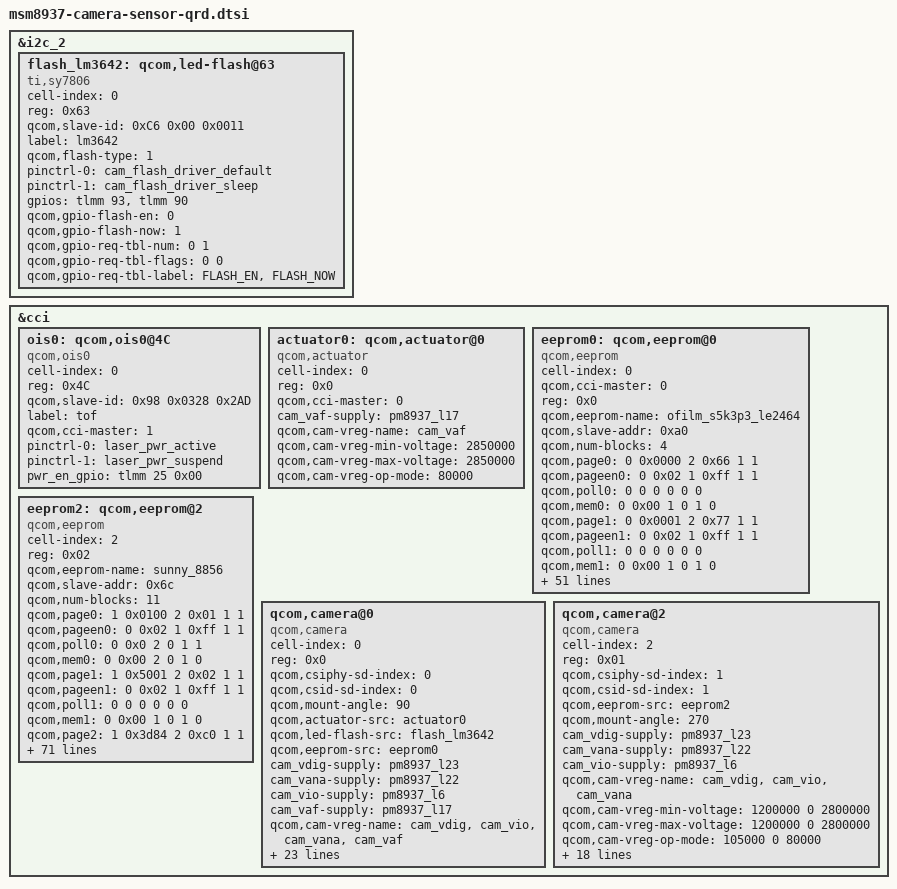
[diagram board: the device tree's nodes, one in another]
/*
 * Copyright (c) 2015-2016, The Linux Foundation. All rights reserved.
 *
 * This program is free software; you can redistribute it and/or modify
 * it under the terms of the GNU General Public License version 2 and
 * only version 2 as published by the Free Software Foundation.
 *
 * This program is distributed in the hope that it will be useful,
 * but WITHOUT ANY WARRANTY; without even the implied warranty of
 * MERCHANTABILITY or FITNESS FOR A PARTICULAR PURPOSE.  See the
 * GNU General Public License for more details.
 */

 //add by allen yao for flash driver ic
&i2c_2 {
	flash_lm3642:qcom,led-flash@63 {
		cell-index = <0>;
		reg = <0x63>;
		qcom,slave-id = <0xC6 0x00 0x0011>;
		compatible = "ti,sy7806";
		label = "lm3642";
		qcom,flash-type = <1>;
		pinctrl-names = "cam_flash_driver_default","cam_flash_driver_sleep";
		pinctrl-0 = <&cam_flash_driver_default>;
		pinctrl-1 = <&cam_flash_driver_sleep>;
		gpios = <&tlmm 93 0>,
			<&tlmm 90 0>;
		qcom,gpio-flash-en = <0>;
		qcom,gpio-flash-now = <1>;
		qcom,gpio-req-tbl-num = <0 1>;
		qcom,gpio-req-tbl-flags = <0 0>;
		qcom,gpio-req-tbl-label = "FLASH_EN",
			"FLASH_NOW";
	};

};

 
&cci {

	ois0: qcom,ois0@4C {
		cell-index = <0>;
		reg = <0x4C>;
		qcom,slave-id = <0x98 0x0328 0x2AD>;
		compatible = "qcom,ois0";
		label = "tof";
		qcom,cci-master = <1>;
		pinctrl-names = "laser_active","laser_suspend";
		pinctrl-0 = <&laser_pwr_active>;
		pinctrl-1 = <&laser_pwr_suspend>;
		pwr_en_gpio = <&tlmm 25 0x00>;
		/*
		laser_power-supply = <&pm8937_l10>;
		cam_cci-supply = <&pm8937_l6>;
		qcom,cam-vreg-name = "laser_power","cam_cci";
		qcom,cam-vreg-min-voltage = <2850000 1800000>;
		qcom,cam-vreg-max-voltage = <2900000 1800000>;
		qcom,cam-vreg-op-mode = <80000 100000>;
		*/
	};

	actuator0: qcom,actuator@0 {
		cell-index = <0>;
		reg = <0x0>;
		compatible = "qcom,actuator";
		qcom,cci-master = <0>;
		cam_vaf-supply = <&pm8937_l17>;
		qcom,cam-vreg-name = "cam_vaf";
		qcom,cam-vreg-min-voltage = <2850000>;
		qcom,cam-vreg-max-voltage = <2850000>;
		qcom,cam-vreg-op-mode = <80000>;
	};

	eeprom0: qcom,eeprom@0 {
		cell-index = <0>;
		compatible = "qcom,eeprom";
		qcom,cci-master = <0>;
		reg = <0x0>;

		//add by allenyao
		qcom,eeprom-name = "ofilm_s5k3p3_le2464";
		//compatible = "qcom,eeprom";
		qcom,slave-addr = <0xa0>;
		//qcom,cci-master = <0>;
		qcom,num-blocks = <4>;
		
		qcom,page0 = <0 0x0000 2 0x66 1 1>;
		qcom,pageen0 = <0 0x02 1 0xff 1 1>;
		qcom,poll0 = <0 0 0 0 0 0>;
		qcom,mem0 = <0 0x00 1 0 1 0>;
		
		qcom,page1 = < 0 0x0001 2 0x77 1 1>;
		qcom,pageen1 = <0 0x02 1 0xff 1 1>;
		qcom,poll1 = <0 0 0 0 0 0>;
		qcom,mem1 = <0 0x00 1 0 1 0>;

		qcom,page2 = <0 0x0002 2 0x88 1 1>;
		qcom,pageen2 = <0 0x02 1 0xff 1 1>;
		qcom,poll2 = <0 0 0 0 0 0>;
		qcom,mem2 = <0 0x00 1 0 1 0>;

		qcom,page3 = <0 0x00 1 0x55 1 1>;
		qcom,pageen3 = <0 0x02 1 0xff 1 1>;
		qcom,poll3 = <0 0x0 2 0 1 1>;
		qcom,mem3 = <2205 0x00 2 0 1 0>;
		
		qcom,saddr4 = <0xaa>;
		qcom,page4 = <0 0x00 1 0x99 1 1>;
		qcom,pageen4 = <0 0x02 1 0xff 1 1>;
		qcom,poll4 = <0 0 0 0 0 0>;
		qcom,mem4 = <255 0x00 1 0 1 0>;
		
		qcom,saddr5 = <0xac>;
		qcom,page5 = <0 0x00 1 0x11 1 1>;
		qcom,pageen5 = <0 0x02 1 0xff 1 1>;
		qcom,poll5 = <0 0 0 0 0 0>;
		qcom,mem5 = <85 0x00 1 0 1 0>;
		//end 

		
		cam_vdig-supply = <&pm8937_l23>;
		cam_vana-supply = <&pm8937_l22>;
		cam_vio-supply = <&pm8937_l6>;
		cam_vaf-supply = <&pm8937_l17>;
		qcom,cam-vreg-name = "cam_vdig", "cam_vio", "cam_vana",
							"cam_vaf";
		qcom,cam-vreg-min-voltage = <1200000 0 2800000 2850000>;
		qcom,cam-vreg-max-voltage = <1200000 0 2800000 2850000>;
		qcom,cam-vreg-op-mode = <200000 0 80000 100000>;
		pinctrl-names = "cam_default", "cam_suspend";
		pinctrl-0 = <&cam_sensor_mclk0_default
				&cam_sensor_rear_default>;
		pinctrl-1 = <&cam_sensor_mclk0_sleep &cam_sensor_rear_sleep>;
		gpios = <&tlmm 26 0>,
			<&tlmm 36 0>,
			<&tlmm 42 0>;
		qcom,gpio-reset = <1>;
		qcom,gpio-standby = <2>;
		qcom,gpio-req-tbl-num = <0 1 2>;
		qcom,gpio-req-tbl-flags = <1 0 0>;
		qcom,gpio-req-tbl-label = "CAMIF_MCLK0",
			"CAM_RESET0",
			"CAM_STANDBY0";
		status = "ok";

		//add by allenyao
		qcom,cam-power-seq-type = "sensor_vreg",
			"sensor_vreg", "sensor_vreg",
			"sensor_gpio", "sensor_gpio",
			"sensor_clk";
		qcom,cam-power-seq-val = "cam_vio",
			"cam_vana", "cam_vdig",
			"sensor_gpio_reset",
			"sensor_gpio_standby",
			"sensor_cam_mclk" ;
		qcom,cam-power-seq-cfg-val = <1 1 1 1 1 24000000>;
		qcom,cam-power-seq-delay = <10 10 10 10 10 5>;
		//end
		
		clocks = <&clock_gcc clk_mclk0_clk_src>,
				<&clock_gcc clk_gcc_camss_mclk0_clk>;
		clock-names = "cam_src_clk", "cam_clk";
		qcom,clock-rates = <19200000 0>;
	};

	eeprom2: qcom,eeprom@2 {
		cell-index = <2>;
		compatible = "qcom,eeprom";
		reg = <0x02>;
		
		//add by allenyao
		qcom,eeprom-name = "sunny_8856";
		//compatible = "qcom,eeprom";
		qcom,slave-addr = <0x6c>;
		//qcom,cci-master = <0>;
		qcom,num-blocks = <11>;
		
		qcom,page0 = <1 0x0100 2 0x01 1 1>;
		qcom,pageen0 = <0 0x02 1 0xff 1 1>;
		qcom,poll0 = <0 0x0 2 0 1 1>;
		qcom,mem0 = <0 0x00 2 0 1 0>;

		qcom,page1 = <1 0x5001 2 0x02 1 1>;
		qcom,pageen1 = <0 0x02 1 0xff 1 1>;
		qcom,poll1 = <0 0 0 0 0 0>;
		qcom,mem1 = <0 0x00 1 0 1 0>;
		
		qcom,page2 = <1 0x3d84 2 0xc0 1 1>;
		qcom,pageen2 = <0 0x02 1 0xff 1 1>;
		qcom,poll2 = <0 0 0 0 0 0>;
		qcom,mem2 = <0 0x00 1 0 1 0>;

		qcom,page3 = <1 0x3d88 2 0x70 1 1>;//start high add
		qcom,pageen3 = <0 0x02 1 0xff 1 1>;
		qcom,poll3 = <0 0 0 0 0 0>;
		qcom,mem3 = <0 0x00 1 0 1 0>;
		
		qcom,page4 = <1 0x3d89 2 0x10 1 1>;//start low add
		qcom,pageen4 = <0 0x02 1 0xff 1 1>;
		qcom,poll4 = <0 0 0 0 0 0>;
		qcom,mem4 = <0 0x00 1 0 1 0>;
		
		qcom,page5 = <1 0x3d8a 2 0x72 1 1>;//end high add
		qcom,pageen5 = <0 0x02 1 0xff 1 1>;
		qcom,poll5 = <0 0 0 0 0 0>;
		qcom,mem5 = <0 0x00 1 0 1 0>;

		qcom,page6 = <1 0x3d8b 2 0x03 1 1>;//end low add
		qcom,pageen6 = <0 0x02 1 0xff 1 1>;
		qcom,poll6 = <0 0 0 0 0 0>;
		qcom,mem6 = <0 0x00 1 0 1 0>;

		qcom,page7 = <1 0x3d81 2 0x01 1 10>;//load otp data into buffer
		qcom,pageen7 = <0 0x02 1 0xff 1 1>;
		qcom,poll7 = <0 0 0 0 0 0>;
		qcom,mem7 = <0 0x7203 2 0 1 0>;

		qcom,page8 = <0 0x00 1 0x11 1 1>;
		qcom,pageen8 = <0 0x02 1 0xff 1 1>;
		qcom,poll8 = <0 0 0 0 0 0>;
		qcom,mem8 = <500 0x7010 2 0 1 0>; //read data
		
		qcom,page9 = <0 0x00 1 0x11 1 1>;
		qcom,pageen9 = <0 0x02 1 0xff 1 1>;
		qcom,poll9 = <0 0 0 0 0 0>;
		qcom,mem9 = <0 0x00 1 0 1 0>;
		qcom,clear9 = <500 0x7010 2 0 1 0>; //clear buff

		qcom,page10 = <1 0x5001 2 0x0a 1 1>;
		qcom,pageen10 = <0 0x02 1 0xff 1 1>;
		qcom,poll10 = <0 0 0 0 0 0>;
		qcom,mem10 = <0 0x7203 2 0 1 0>;
		//end 
		
		cam_vdig-supply = <&pm8937_l23>;
		cam_vana-supply = <&pm8937_l22>;
		cam_vio-supply = <&pm8937_l6>;
		cam_vaf-supply = <&pm8937_l17>;
		qcom,cam-vreg-name = "cam_vdig", "cam_vio", "cam_vana",
								"cam_vaf";
		qcom,cam-vreg-min-voltage = <1200000 0 2800000 2850000>;
		qcom,cam-vreg-max-voltage = <1200000 0 2800000 2850000>;
		qcom,cam-vreg-op-mode = <105000 0 80000 100000>;
		qcom,gpio-no-mux = <0>;
		pinctrl-names = "cam_default", "cam_suspend";
		pinctrl-0 = <&cam_sensor_mclk2_default
					&cam_sensor_front1_default>;
		pinctrl-1 = <&cam_sensor_mclk2_sleep
					&cam_sensor_front1_sleep>;
		gpios = <&tlmm 28 0>,
			<&tlmm 40 0>,
			<&tlmm 39 0>;
		qcom,gpio-reset = <1>;
		qcom,gpio-standby = <2>;
		qcom,gpio-req-tbl-num = <0 1 2>;
		qcom,gpio-req-tbl-flags = <1 0 0>;
		qcom,gpio-req-tbl-label = "CAMIF_MCLK2",
					  "CAM_RESET2",
					  "CAM_STANDBY2";
		qcom,cci-master = <0>;
		status = "ok";
		//add by allenyao
		qcom,cam-power-seq-type = "sensor_vreg",
			"sensor_vreg", "sensor_vreg",
			"sensor_gpio", "sensor_gpio",
			"sensor_clk";
		qcom,cam-power-seq-val = "cam_vio",
			"cam_vana", "cam_vdig",
			"sensor_gpio_reset",
			"sensor_gpio_standby",
			"sensor_cam_mclk" ;
		qcom,cam-power-seq-cfg-val = <1 1 1 1 1 24000000>;
		qcom,cam-power-seq-delay = <10 10 10 10 10 5>;
		//end
		clocks = <&clock_gcc clk_mclk2_clk_src>,
			<&clock_gcc clk_gcc_camss_mclk2_clk>;
		clock-names = "cam_src_clk", "cam_clk";
		qcom,clock-rates = <19200000 0>;
	};

	qcom,camera@0 {
		cell-index = <0>;
		compatible = "qcom,camera";
		reg = <0x0>;
		qcom,csiphy-sd-index = <0>;
		qcom,csid-sd-index = <0>;
		qcom,mount-angle = <90>;
		qcom,actuator-src = <&actuator0>;
		qcom,led-flash-src = <&flash_lm3642>;
		qcom,eeprom-src = <&eeprom0>;
		cam_vdig-supply = <&pm8937_l23>;
		cam_vana-supply = <&pm8937_l22>;
		cam_vio-supply = <&pm8937_l6>;
		cam_vaf-supply = <&pm8937_l17>;
		qcom,cam-vreg-name = "cam_vdig", "cam_vio", "cam_vana",
							"cam_vaf";
		qcom,cam-vreg-min-voltage = <1200000 0 2800000 2850000>;
		qcom,cam-vreg-max-voltage = <1200000 0 2800000 2850000>;
		qcom,cam-vreg-op-mode = <200000 0 80000 100000>;
		pinctrl-names = "cam_default", "cam_suspend";
		pinctrl-0 = <&cam_sensor_mclk0_default
				&cam_sensor_rear_default>;
		pinctrl-1 = <&cam_sensor_mclk0_sleep
				&cam_sensor_rear_sleep>;
		gpios = <&tlmm 26 0>,
			<&tlmm 36 0>,
			<&tlmm 42 0>,
			<&tlmm 35 0>;
		qcom,gpio-reset = <1>;
		qcom,gpio-standby = <2>;
		qcom,gpio-afen = <3>;
		qcom,gpio-req-tbl-num = <0 1 2 3>;
		qcom,gpio-req-tbl-flags = <1 0 0 0>;
		qcom,gpio-req-tbl-label = "CAMIF_MCLK0",
			"CAM_RESET0",
			"CAM_STANDBY0",
			"CAM_AFEN";
		qcom,sensor-position = <0>;
		qcom,sensor-mode = <0>;
		qcom,cci-master = <0>;
		clocks = <&clock_gcc clk_mclk0_clk_src>,
			<&clock_gcc clk_gcc_camss_mclk0_clk>;
		clock-names = "cam_src_clk", "cam_clk";
		qcom,clock-rates = <24000000 0>;
	};

	qcom,camera@2 {
		cell-index = <2>;
		compatible = "qcom,camera";
		reg = <0x01>;
		qcom,csiphy-sd-index = <1>;
		qcom,csid-sd-index = <1>;
		qcom,eeprom-src = <&eeprom2>;
		qcom,mount-angle = <270>;
		cam_vdig-supply = <&pm8937_l23>;
		cam_vana-supply = <&pm8937_l22>;
		cam_vio-supply = <&pm8937_l6>;
		qcom,cam-vreg-name = "cam_vdig", "cam_vio", "cam_vana";
		qcom,cam-vreg-min-voltage = <1200000 0 2800000>;
		qcom,cam-vreg-max-voltage = <1200000 0 2800000>;
		qcom,cam-vreg-op-mode = <105000 0 80000>;
		qcom,gpio-no-mux = <0>;
		pinctrl-names = "cam_default", "cam_suspend";
		pinctrl-0 = <&cam_sensor_mclk2_default
				&cam_sensor_front1_default>;
		pinctrl-1 = <&cam_sensor_mclk2_sleep
				&cam_sensor_front1_sleep>;
		gpios = <&tlmm 28 0>,
			<&tlmm 40 0>,
			<&tlmm 39 0>;
		qcom,gpio-reset = <1>;
		qcom,gpio-standby = <2>;
		qcom,gpio-req-tbl-num = <0 1 2>;
		qcom,gpio-req-tbl-flags = <1 0 0>;
		qcom,gpio-req-tbl-label = "CAMIF_MCLK2",
					  "CAM_RESET2",
					  "CAM_STANDBY2";
		qcom,sensor-position = <1>;
		qcom,sensor-mode = <0>;
		qcom,cci-master = <0>;
		clocks = <&clock_gcc clk_mclk2_clk_src>,
			<&clock_gcc clk_gcc_camss_mclk2_clk>;
		clock-names = "cam_src_clk", "cam_clk";
		qcom,clock-rates = <24000000 0>;
	};
};
